# host_dma_secure register map
Vendor: Texas Instruments
Peripheral module from a debugger description file (folder CC35X1E).
Registers are 32-bit, access per field, reset 0x0 unless marked. A register's access mark holds for its fields unless they carry their own. Offsets are as the file gives them; lines under a group give offsets from that group; [hi:lo] are bit positions; {n}, {i} and the like mark numbered series; 'fields as' and 'values as' point back to an identical list; <NAME> marks a mode.

## host_dma_secure
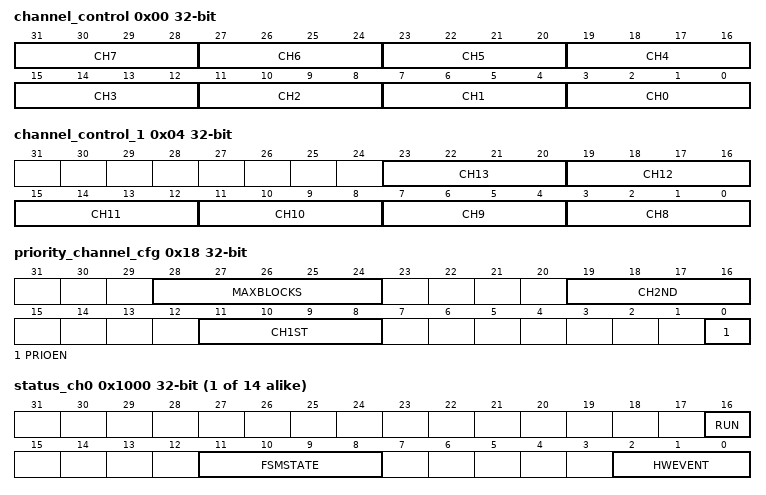
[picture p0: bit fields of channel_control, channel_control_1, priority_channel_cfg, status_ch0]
0x00 channel_control rw — Host DMA Channel Controlled by Defined Peripheral. The value of each fields concats with [HOST_DMA:JOBCTLCHx.SRCDSTCFG] (when x is channel num) if [CHCTL0.CHx] = 4 and [JOBCTLCHx.SRCDSTCFG] = 1 (value = 0100_1 = 9) then flow control signals of channel x are connected to periph number 9 flow control signals Note: [CHCTL0.CHx] = 0xF is forbidden. This configuration should be only used for Dynamic Switch
  [4n+3:4n] CH{n} (n=0..7) — Channel {n} Control. Flow control signals: 22 HIF 21 Not Valid - PDM has only read 20 PDM 19 Not Valid - ADC has only read 18 ADC 17 MCAN 1 16 MCAN 0 15 SDIO TX 14 SDIO RX 13 SDMMC TX 12 SDMMC RX 11 I2C TX 10 I2C RX 9 I2C TX 8 I2C RX 7 SPI TX 6 SPI RX 5 SPI TX 4 SPI RX 3 UART TX 2 UART RX 1 UART TX 0 UART RX
0x04 channel_control_1 — Host DMA Channel Controlled by Defined Peripheral. The value of each fields concats with [HOST_DMA:JOBCTLCHx.SRCDSTCFG] (when x is channel num) if [CHCTL1.CHx] = 4 and [JOBCTLCHx.SRCDSTCFG] = 1 (value = 0100_1 = 9) then flow control signals of channel x are connected to periph number 9 flow control signals Note: [CHCTL0.CHx] = 0xF is forbidden. This configuration should be only used for Dynamic Switch
  [4n-29:4n-32] CH{n} rw (n=8..13) — Channel {n} Control. Flow control signals: 22 HIF 21 Not Valid - PDM has only read 20 PDM 19 Not Valid - ADC has only read 18 ADC 17 MCAN 1 16 MCAN 0 15 SDIO TX 14 SDIO RX 13 SDMMC TX 12 SDMMC RX 11 I2C TX 10 I2C RX 9 I2C TX 8 I2C RX 7 SPI TX 6 SPI RX 5 SPI TX 4 SPI RX 3 UART TX 2 UART RX 1 UART TX 0 UART RX
0x18 priority_channel_cfg reset not defined — Priority Channel Configuration.
  [28:24] MAXBLOCKS rw — Maximum consecutive priority blocks. Maximum consecutive block transactions of "priority channels" . After this number of consecutive blocks one of "roubd robin" channels will win arbitration. 31 means there is no limitation on number of consecutive priority blocks
  [19:16] CH2ND rw — Second priority channel. channel with second highest prioriry
  [11:8] CH1ST rw — First priority channel. channel with highest prioriry
  [0] PRIOEN rw — Enable priority channel. Enable one channel to be prioritize - no round rubin would be done
{0x1000+0x1000*i} status_ch{i} ro (i=0..13) — Channel Status FSM state and run indication.
  [16] RUN — Indication that channel is currently transfering data and is not idle. Channels that are waiting on arbitration are considered running.
  [11:8] FSMSTATE — FSM state: 0x0. IDLE 0x2. EXCEPTION 0x3. DRAIN 0x4. ABORT 0x8. PENDING ARB 0x9. COPY 0xA. COPY LAST 0xC. DONE 0xD. SAVE CTX 0xE. WAIT NEXT TRANS 0xF. LAST
  [2:0] HWEVENT — HW event status. Channel status is a bit mask. Multiple bits can be set at the same time 0. PROCESSING 1. TRANS DONE 2. ABORT 4. EXCEPTION
0x1004 trans_iptr_ch0 rw — Input Pointer Channel Transaction. 32 bit address pointer of channel current input.
  [31:0] IPTR — Transaction input pointer. 32 bit address pointer of channel current input.
0x1008 trans_optr_ch0 rw — Output Pointer Channel Transaction. 32 bit address pointer of channel current output.
  [31:0] OPTR — Transaction output pointer. 32 bit address pointer of channel current output.
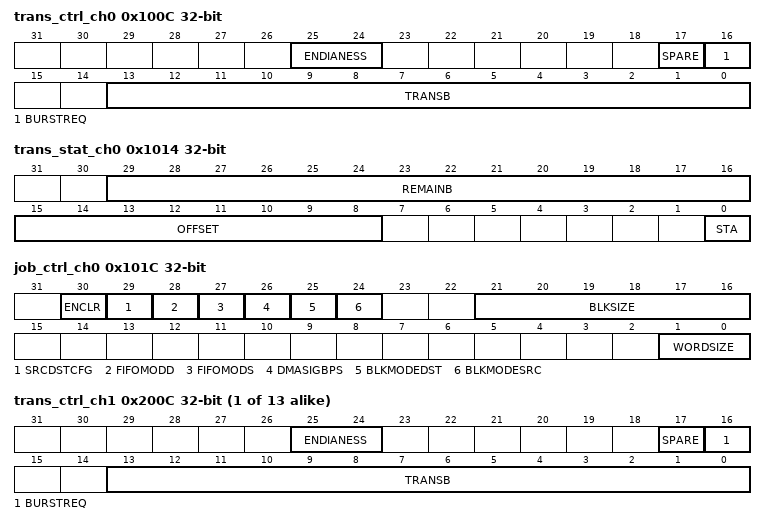
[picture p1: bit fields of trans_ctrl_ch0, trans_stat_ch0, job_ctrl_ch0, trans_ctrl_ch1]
0x100C trans_ctrl_ch0 — Transaction control
  [25:24] ENDIANESS rw — 0 -no endianess, 1 - byte endianess, 2 - bit endianess
  [17] SPARE rw
  [16] BURSTREQ rw — Use burst request. In case number of words to tranfer smaller than block size, DMA would use signle request and work with block size of 1 word. In case we know request would be set on altough number of words to tranfer is smaller than block size, we can set this field on and DMA will wait for block_request and transact all remaining words in one block.
  [13:0] TRANSB rw — Transaction bytes number. Number of bytes of the transaction to move from source to destination.
0x1010 trans_ctrl2_ch0 — DMA command interface
  [2:0] CMD wo — 1 - run command. Start a transaction. 2- abort command - stop reansaction. 4- init command - init new transaction afet abort/error. Type:Write-Clear.
0x1014 trans_stat_ch0 ro — Transaction Status. Job completion reason - either last transaction or exception
  [29:16] REMAINB — Remain bytes number. Number of bytes remaining to complete the transaction.
  [15:8] OFFSET — Word offset. Offset in words from block boundary. Actually number of word have been transferred in this block
  [0] STA — channel OCP rstatus recieved at one of the primary ports. Once an error is encountered the channel will enter an Exception state and stay the until an init command is recieved. ICLR does not affect this status.
0x101C job_ctrl_ch0 — Job control register
  [30] ENCLR rw — Enable DMA to set a rd/wr clear pulse at the beginning of a job (one cycle after run cmd)
  [29] SRCDSTCFG rw — 0 - Sorce is periph: transaction from periph to memory. 1 - Destination is periph :transaction from Memory to periph
  [28] FIFOMODD rw — Destination pointer fifo mode
  [27] FIFOMODS rw — Source pointer fifo mode
  [26] DMASIGBPS rw — Tie high channel DMA req signal. This is useful for memory to memort transaction
  [25] BLKMODEDST rw — Destination pointer wrap around mode 0: no wrap around(non block mode) 1: with wrap around(block mode)
  [24] BLKMODESRC rw — source pointer wrap around mode 0: no wrap around(non block mode) 1: with wrap around(block mode)
  [21:16] BLKSIZE rw — size of the block in words. If block mode is enabled, defines the address wrap around. Since channel arbitration decisions are made every block, this also effect how much bandwidth is given to a specific channel.
  [1:0] WORDSIZE rw — 00 -word size is 32 bits 01 -word size is 16 bits 10 -word size is 8 bits
{0x1004+0x1000*i} trans_iptr_ch{i} rw (i=1..3) — 32 bit address pointer of channel current input.
  [31:0] IPTR
{0x1008+0x1000*i} trans_optr_ch{i} rw (i=1..13) — 32 bit address pointer of channel current output.
  [31:0] OPTR
{0x100C+0x1000*i} trans_ctrl_ch{i} (i=1..13) — Transaction control
  [25:24] ENDIANESS rw — 0 -no endianess, 1 - byte endianess, 2 - bit endianess
  [17] SPARE rw
  [16] BURSTREQ rw — In case number of words to tranfer smaller than block size, DMA would use signle request and work with block size of 1 word. In case we know request would be set on altough number of words to tranfer is smaller than block size, we can set this field on and DMA will wait for block_request and transact all remaining words in one block.
  [13:0] TRANSB rw — Number of bytes of the transaction to move from source to destination.
{0x1010+0x1000*i} trans_ctrl2_ch{i} (i=1..13) — DMA command interface
  [2:0] CMD wo — 1 - run command. Start a transaction. 2- abort command - stop reansaction. 4- init command - init new transaction afet abort/error.
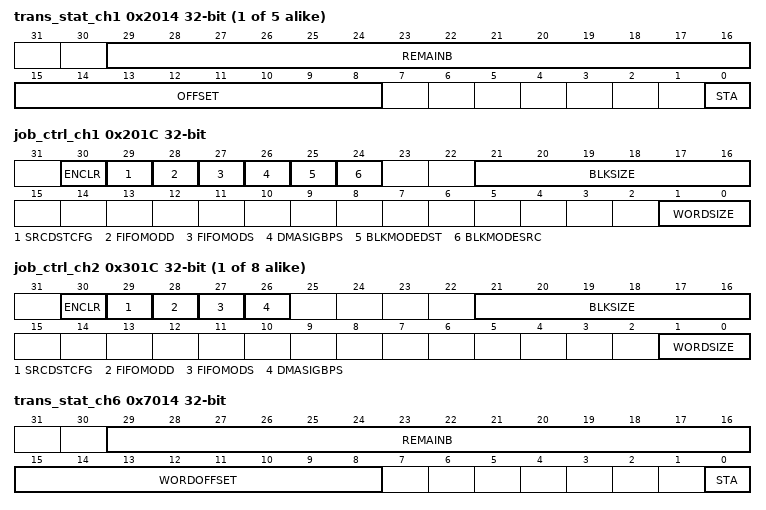
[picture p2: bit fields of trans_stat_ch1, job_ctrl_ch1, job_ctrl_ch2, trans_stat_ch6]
{0x1014+0x1000*i} trans_stat_ch{i} ro (i=1..5) — Job completion reason - either last transaction or exception
  [29:16] REMAINB — Number of bytes remaining to complete the transaction.
  [15:8] OFFSET — Offset in words from block boundary. Actually number of word have been transferred in this block
  [0] STA — channel OCP rstatus recieved at one of the primary ports. Once an error is encountered the channel will enter an Exception state and stay the until an init command is recieved. ICLR does not affect this status.
0x201C job_ctrl_ch1 — Job control register
  fields as job_ctrl_ch0
{0x101C+0x1000*i} job_ctrl_ch{i} (i=2..9) — Job control register
  [30] ENCLR rw — Enable DMA to set a rd/wr clear pulse at the beginning of a job (one cycle after run cmd)
  [29] SRCDSTCFG rw — 0 - Sorce is periph: transaction from periph to memory. 1 - Destination is periph :transaction from Memory to periph
  [28] FIFOMODD rw — Destination pointer fifo mode
  [27] FIFOMODS rw — Source pointer fifo mode
  [26] DMASIGBPS rw — Tie high channel DMA req signal. This is useful for memory to memort transaction
  [21:16] BLKSIZE rw — size of the block in words. If block mode is enabled, defines the address wrap around. Since channel arbitration decisions are made every block, this also effect how much bandwidth is given to a specific channel.
  [1:0] WORDSIZE rw — 00 -word size is 32 bits 01 -word size is 16 bits 10 -word size is 8 bits
0x5004 trans_iptr_ch4 rw — 32 bit address pointer of channel current input.
  [31:0] INPTR
{0x1004+0x1000*i} trans_iptr_ch{i} rw (i=5..13) — 32 bit address pointer of channel current input.
  [31:0] IPTR
0x7014 trans_stat_ch6 ro — Job completion reason - either last transaction or exception
  [29:16] REMAINB — Number of bytes remaining to complete the transaction.
  [15:8] WORDOFFSET — Offset in words from block boundary. Actually number of word have been transferred in this block
  [0] STA — channel OCP rstatus recieved at one of the primary ports. Once an error is encountered the channel will enter an Exception state and stay the until an init command is recieved. ICLR does not affect this status.
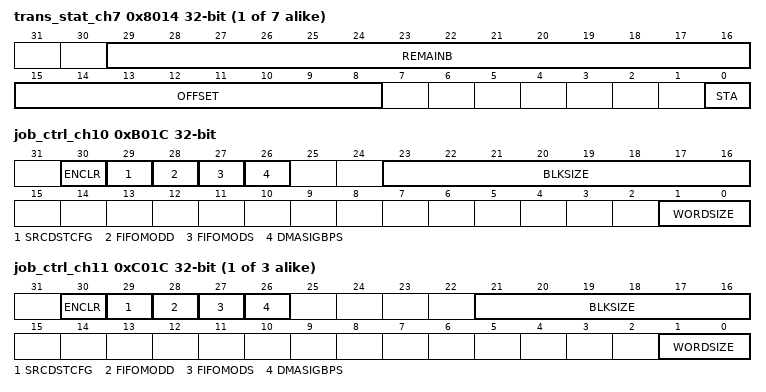
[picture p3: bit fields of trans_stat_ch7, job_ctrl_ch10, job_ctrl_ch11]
{0x1014+0x1000*i} trans_stat_ch{i} ro (i=7..13) — Job completion reason - either last transaction or exception
  fields as trans_stat_ch1
0xB01C job_ctrl_ch10 — Job control register
  [30] ENCLR rw — Enable DMA to set a rd/wr clear pulse at the beginning of a job (one cycle after run cmd)
  [29] SRCDSTCFG rw — 0 - Sorce is periph: transaction from periph to memory. 1 - Destination is periph :transaction from Memory to periph
  [28] FIFOMODD rw — Destination pointer fifo mode
  [27] FIFOMODS rw — Source pointer fifo mode
  [26] DMASIGBPS rw — Tie high channel DMA req signal. This is useful for memory to memort transaction
  [23:16] BLKSIZE rw — size of the block in words. If block mode is enabled, defines the address wrap around. Since channel arbitration decisions are made every block, this also effect how much bandwidth is given to a specific channel.
  [1:0] WORDSIZE rw — 00 -word size is 32 bits 01 -word size is 16 bits 10 -word size is 8 bits
{0x101C+0x1000*i} job_ctrl_ch{i} (i=11..13) — Job control register
  fields as job_ctrl_ch2
